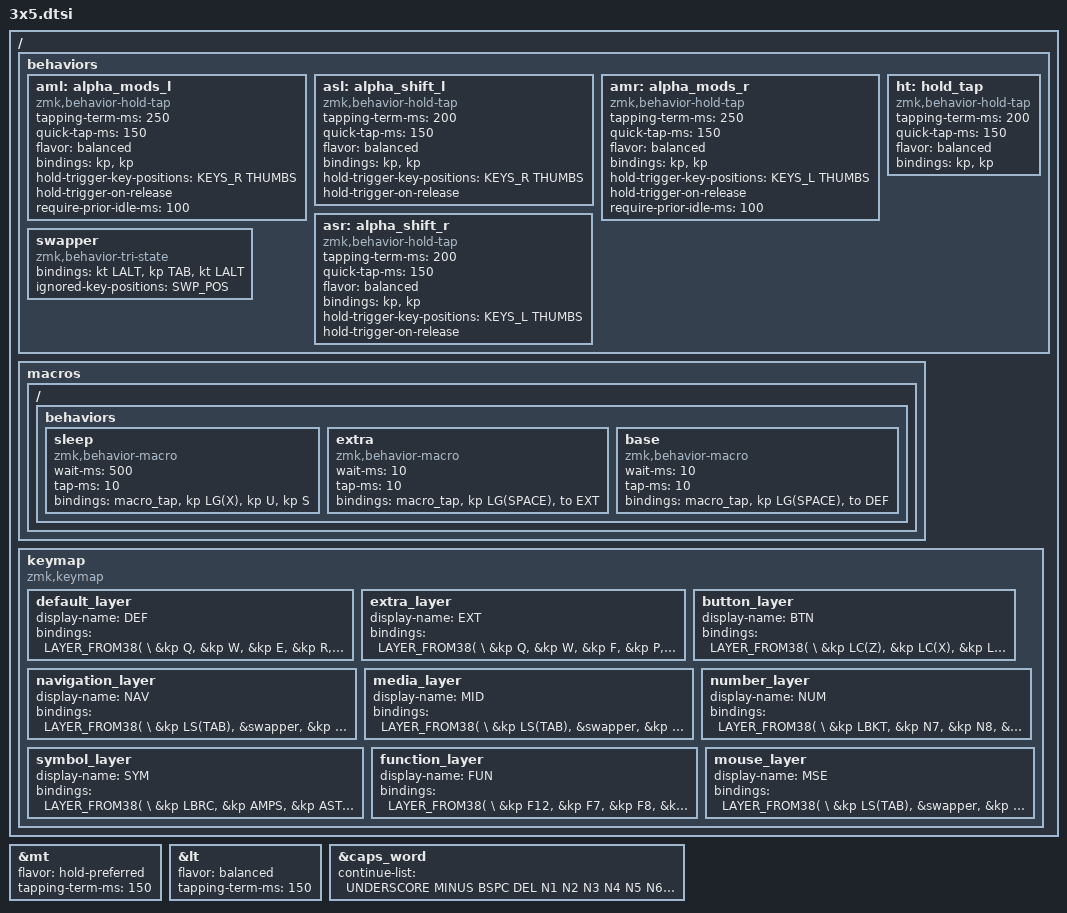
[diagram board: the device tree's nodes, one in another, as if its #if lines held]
#include <behaviors.dtsi>
#include <dt-bindings/zmk/keys.h>
#include <dt-bindings/zmk/bt.h>
#include <dt-bindings/zmk/outputs.h>

// Layer aliases
#define DEF 0
#define EXT 1
#define BTN 2
#define NAV 3
#define MID 4
#define NUM 5
#define SYM 6
#define FUN 7
#define MSE 8

// Desktop and tab navigation shortcuts
#define D_LT   LC(LG(LEFT))
#define D_RT   LC(LG(RIGHT))
#define TAB_RT LC(TAB)
#define TAB_LT LC(LS(TAB))

// Extra key bindings
#define SWP_POS LT4 RT4

#include "combos.dtsi"

#ifdef MOUSE_KEYS
#    include "mouse.dtsi"
#    define MS_ACT(key) &lt MSE key
#else
#    define MS_ACT(key) &kp key
#endif

&mt {
    flavor = "hold-preferred";
    tapping-term-ms = <150>;
};

&lt {
    flavor = "balanced";
    tapping-term-ms = <150>;
};

&caps_word {
    continue-list = <UNDERSCORE MINUS BSPC DEL N1 N2 N3 N4 N5 N6 N7 N8 N9 N0>;
};

/ {
    behaviors {
        aml: alpha_mods_l {
            compatible = "zmk,behavior-hold-tap";
            #binding-cells = <2>;
            tapping-term-ms = <250>;
            quick-tap-ms = <150>;
            flavor = "balanced";
            bindings = <&kp>, <&kp>;
            hold-trigger-key-positions = <KEYS_R THUMBS>;
            hold-trigger-on-release;
            require-prior-idle-ms = <100>;
        };
        asl: alpha_shift_l {
            compatible = "zmk,behavior-hold-tap";
            #binding-cells = <2>;
            tapping-term-ms = <200>;
            quick-tap-ms = <150>;
            flavor = "balanced";
            bindings = <&kp>, <&kp>;
            hold-trigger-key-positions = <KEYS_R THUMBS>;
            hold-trigger-on-release;
        };
        amr: alpha_mods_r {
            compatible = "zmk,behavior-hold-tap";
            #binding-cells = <2>;
            tapping-term-ms = <250>;
            quick-tap-ms = <150>;
            flavor = "balanced";
            bindings = <&kp>, <&kp>;
            hold-trigger-key-positions = <KEYS_L THUMBS>;
            hold-trigger-on-release;
            require-prior-idle-ms = <100>;
        };
        asr: alpha_shift_r {
            compatible = "zmk,behavior-hold-tap";
            #binding-cells = <2>;
            tapping-term-ms = <200>;
            quick-tap-ms = <150>;
            flavor = "balanced";
            bindings = <&kp>, <&kp>;
            hold-trigger-key-positions = <KEYS_L THUMBS>;
            hold-trigger-on-release;
        };

        // Swapper for smart alt+tab
        swapper: swapper {
            compatible = "zmk,behavior-tri-state";
            #binding-cells = <0>;
            bindings = <&kt LALT>, <&kp TAB>, <&kt LALT>;
            ignored-key-positions = <SWP_POS>;    //<SWP_POS>; &kp LS(TAB) position
        };

        ht: hold_tap {
            compatible = "zmk,behavior-hold-tap";
            #binding-cells = <2>;
            tapping-term-ms = <200>;
            quick-tap-ms = <150>;
            flavor = "balanced";
            bindings = <&kp>, <&kp>;
        };

    };

    macros {
        ZMK_MACRO(sleep,
            wait-ms = <500>;
            tap-ms = <10>;
            bindings
                = <&macro_tap &kp LG(X) &kp U &kp S>;
        )
// 시간및언어>언어및지역>기본설정언어 한국어, 영어(미국) 2가지가 있을 때 작동
        ZMK_MACRO(extra,
            wait-ms = <10>;
            tap-ms = <10>;
            bindings
                = <&macro_tap &kp LG(SPACE) &to EXT>;
        )
        ZMK_MACRO(base,
            wait-ms = <10>;
            tap-ms = <10>;
            bindings
                = <&macro_tap &kp LG(SPACE) &to DEF>;
        )
    };

    keymap {
        compatible = "zmk,keymap";

        default_layer {
            display-name = "DEF";
            bindings = <LAYER_FROM38( \
//           ╭──────────────┬──────────────┬──────────────┬──────────────┬──────────────╮   ╭──────────────┬──────────────┬──────────────┬──────────────┬──────────────╮
              &kp Q,         &kp W,         &kp E,         &kp R,         &kp T,             &kp Y,         &kp U,         &kp I,         &kp O,         &kp P, \
              &aml LGUI A,   &aml LALT S,   &aml LCTRL D,  &asl LSHFT F,  &kp G,             &kp H,         &asr LSHFT J,  &amr LCTRL K,  &amr LALT L,   &aml LGUI SEMI, \
&kp CAPS,      &lt BTN Z,     &kp X,         &kp C,         &kp V,         &lt MID B,         &lt FUN N,     &kp M,        &amr RCTRL COMMA, &amr RALT DOT, &lt BTN SLASH, &kp SQT, \
                                            MS_ACT(TAB),   &lt NAV SPACE, &lt MID ESC,       &lt SYM RET,   &lt NUM BSPC,  &lt FUN DEL \
//                                         ╰─────────────┴──────────────┴──────────────╯    ╰──────────────┴──────────────┴──────────────╯
            )>;
        };

        extra_layer {
            display-name = "EXT";
            bindings = <LAYER_FROM38( \
//           ╭──────────────┬──────────────┬──────────────┬──────────────┬──────────────╮   ╭──────────────┬──────────────┬──────────────┬──────────────┬──────────────╮
              &kp Q,         &kp W,         &kp F,         &kp P,         &kp B,             &kp J,         &kp L,         &kp U,         &kp Y,         &kp SQT, \
              &aml LGUI A,   &aml LALT R,   &aml LCTRL S,  &asl LSHFT T,  &kp G,             &kp M,         &asr LSHFT N,  &amr LCTRL E,  &amr LALT I,   &amr LGUI O, \
&kp CAPS,      &lt BTN  Z,    &kp X,         &kp C,         &kp D,         &lt MID V,         &lt FUN K,     &kp H,        &amr RCTRL COMMA, &amr RALT DOT, &lt BTN SLASH, &kp SQT, \
                                            &lt MID ESC,   &lt NAV SPACE, MS_ACT(TAB),       &lt SYM RET,   &lt NUM BSPC,  &lt FUN DEL \
//                                         ╰──────────────┴──────────────┴──────────────╯   ╰──────────────┴──────────────┴──────────────╯
            )>;
        };

        button_layer {
            display-name = "BTN";
            bindings = <LAYER_FROM38( \
//           ╭──────────────┬──────────────┬──────────────┬──────────────┬──────────────╮   ╭──────────────┬──────────────┬──────────────┬──────────────┬──────────────╮
              &kp LC(Z),     &kp LC(X),     &kp LC(C),     &kp LC(V),     &kp LC(Y),         &kp LC(Y),     &kp LC(V),     &kp LC(C),     &kp LC(X),     &kp LC(Z), \
              &kp LGUI,      &kp LALT,      &kp LCTRL,     &kp LSHFT,     &none,             &none,         &kp LSHFT,     &kp LCTRL,     &kp LALT,      &kp LGUI, \
&kp CAPS,      &kp LC(Z),     &kp LC(X),     &kp LC(C),     &kp LC(V),     &kp LC(Y),         &kp LC(Y),     &kp LC(V),     &kp LC(C),     &kp LC(X),     &kp LC(Z),     &kp SQT, \
                                            &none,         &mkp LCLK,     &mkp RCLK,         &mkp RCLK,     &mkp LCLK,     &none \
//                                         ╰──────────────┴──────────────┴──────────────╯   ╰──────────────┴──────────────┴──────────────╯
            )>;
        };

        navigation_layer {
            display-name = "NAV";
            bindings = <LAYER_FROM38( \
//           ╭──────────────┬──────────────┬──────────────┬──────────────┬──────────────╮   ╭──────────────┬──────────────┬──────────────┬──────────────┬──────────────╮
              &kp LS(TAB),   &swapper,      &kp TAB_RT,    &kp TAB_LT,    &ht LA(F4) LC(F4), &kp INS,       &kp LG(V),      &kp LG(C),        &kp LG(X),       &kp LG(Z), \
              &kp LGUI,      &kp LALT,      &kp LCTRL,     &kp LSHFT,     &none,             &kp LEFT,      &kp UP,      &kp DOWN,      &kp RIGHT,     &kp PG_DN, \
&kp CAPS,      &to EXT,       &to DEF,       &to  NAV,      &to NUM,       &none,             &kp INS,     &kp HOME,     &kp PG_DN,     &kp PG_UP,     &kp END,     &kp SQT, \
                                            &trans,        &trans,        &trans,            &kp RET,       &kp BSPC,      &kp DEL \
//                                         ╰──────────────┴──────────────┴──────────────╯   ╰──────────────┴──────────────┴──────────────╯
            )>;
        };

        media_layer {
            display-name = "MID";
            bindings = <LAYER_FROM38( \
//           ╭──────────────┬──────────────┬──────────────┬──────────────┬──────────────╮   ╭──────────────┬──────────────┬──────────────┬──────────────┬──────────────╮
              &kp LS(TAB),   &swapper,      &kp TAB_RT,    &kp TAB_LT,    &ht LA(F4) LC(F4), &out OUT_USB,  &out OUT_BLE,  &kp C_VOL_UP,  &none,         &none, \
              &kp LGUI,      &kp LALT,      &kp LCTRL,     &kp LSHFT,     &none,             &none,         &kp C_PREV,    &kp C_VOL_DN,  &kp C_NEXT,    &none, \
&kp CAPS,      &to EXT,       &to DEF,       &to MID,       &to FUN,       &trans,            &bt BT_SEL 0,  &bt BT_SEL 1,  &bt BT_SEL 2, &bt BT_CLR,     &bt BT_CLR_ALL, &kp SQT, \
                                            &trans,        &trans,        &trans,            &kp C_STOP,    &kp C_PP,      &kp C_MUTE \
//                                         ╰──────────────┴──────────────┴──────────────╯   ╰──────────────┴──────────────┴──────────────╯
            )>;
        };

        number_layer {
            display-name = "NUM";
            bindings = <LAYER_FROM38( \
//           ╭──────────────┬──────────────┬──────────────┬──────────────┬──────────────╮   ╭──────────────┬──────────────┬──────────────┬──────────────┬──────────────╮
              &kp LBKT,      &kp N7,        &kp N8,        &kp N9,        &kp RBKT,          &ht LA(F4) LC(F4), &kp TAB_LT, &kp TAB_RT,   &swapper,     &kp LS(TAB), \
              &kp SEMI,      &kp N4,        &kp N5,        &kp N6,        &kp EQUAL,         &kp C_AL_CALC, &kp LSHFT,     &kp LCTRL,     &kp LALT,      &kp LGUI, \
&kp CAPS,      &kp GRAVE,     &kp N1,        &kp N2,        &kp N3,        &kp BSLH,          &none,         &to NAV,       &to NUM,       &to DEF,       &to EXT,       &kp SQT, \
                                            &kp DOT,       &kp N0,        &kp MINUS,         &trans,        &trans,        &trans \
//                                         ╰──────────────┴──────────────┴──────────────╯   ╰──────────────┴──────────────┴──────────────╯
            )>;
        };

        symbol_layer {
            display-name = "SYM";
            bindings = <LAYER_FROM38( \
//           ╭──────────────┬──────────────┬──────────────┬──────────────┬──────────────╮   ╭──────────────┬──────────────┬──────────────┬──────────────┬──────────────╮
              &kp LBRC,      &kp AMPS,      &kp ASTRK,     &kp LPAR,      &kp RBRC,          &ht LA(F4) LC(F4), &kp TAB_LT, &kp TAB_RT,   &swapper,      &kp LS(TAB), \
              &kp COLON,     &kp DLLR,      &kp PRCNT,     &kp CARET,     &kp PLUS,          &none,         &kp LSHFT,     &kp LCTRL,     &kp LALT,      &kp LGUI, \
&kp CAPS,      &kp TILDE,     &kp EXCL,      &kp AT,        &kp HASH,      &kp PIPE,          &none,         &to MSE,       &to SYM,       &to DEF,       &to EXT,       &kp SQT, \
                                            &kp LPAR,      &kp RPAR,      &kp UNDER,         &trans,        &trans,        &trans \
//                                         ╰──────────────┴──────────────┴──────────────╯   ╰──────────────┴──────────────┴──────────────╯
            )>;
        };

        function_layer {
            display-name = "FUN";
            bindings = <LAYER_FROM38( \
//           ╭──────────────┬──────────────┬──────────────┬──────────────┬──────────────╮   ╭──────────────┬──────────────┬──────────────┬──────────────┬──────────────╮
              &kp F12,       &kp F7,        &kp F8,        &kp F9,        &kp PSCRN,         &ht LA(F4) LC(F4), &kp TAB_LT, &kp TAB_RT,   &swapper,      &kp LS(TAB), \
              &kp F11,       &kp F4,        &kp F5,        &kp F6,        &kp SLCK,          &none,         &kp LSHFT,     &kp LCTRL,     &kp LALT,      &kp LGUI, \
&kp CAPS,      &kp F10,       &kp F1,        &kp F2,        &kp F3,        &kp PAUSE_BREAK,   &trans,        &to MID,       &to FUN,       &to DEF,       &to EXT,       &kp SQT, \
                                            &kp K_APP,     &kp SPACE,     &kp TAB,           &trans,        &trans,        &trans \
//                                         ╰──────────────┴──────────────┴──────────────╯   ╰──────────────┴──────────────┴──────────────╯
            )>;
        };

#ifdef MOUSE_KEYS
        mouse_layer {
            display-name = "MSE";
            bindings = <LAYER_FROM38( \
//           ╭──────────────┬──────────────┬──────────────┬──────────────┬──────────────╮   ╭──────────────┬──────────────┬──────────────┬──────────────┬──────────────╮
              &kp LS(TAB),   &swapper,      &kp TAB_RT,    &kp TAB_LT,    &ht LA(F4) LC(F4), &none,        &msc SCRL_LEFT, &mmv MOVE_UP,  &msc SCRL_RIGHT, &msc SCRL_UP, \
              &kp LGUI,      &kp LALT,      &kp LCTRL,     &kp LSHFT,     &none,             &none,        &mmv MOVE_LEFT, &mmv MOVE_DOWN, &mmv MOVE_RIGHT, &msc SCRL_DOWN, \
&kp CAPS,      &to EXT,       &to DEF,       &to MSE,       &to SYM,       &none,             &kp LC(Y),     &kp LC(V),     &kp LC(C),     &kp LC(X),     &kp LC(Z),     &kp SQT, \
                                            &trans,        &trans,        &trans,            &mkp RCLK,     &mkp LCLK,     &none \
//                                         ╰──────────────┴──────────────┴──────────────╯   ╰──────────────┴──────────────┴──────────────╯
            )>;
        };
#endif
    };
};
